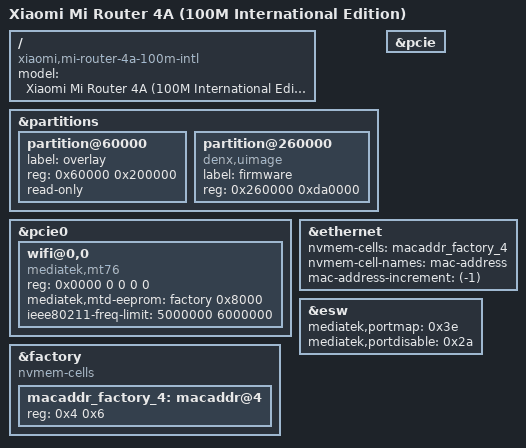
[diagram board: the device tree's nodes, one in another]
// SPDX-License-Identifier: GPL-2.0-or-later OR MIT

#include "mt7628an_xiaomi_mi-router-4.dtsi"

/ {
	compatible = "xiaomi,mi-router-4a-100m-intl", "mediatek,mt7628an-soc";
	model = "Xiaomi Mi Router 4A (100M International Edition)";
};

&partitions {
	partition@60000 {
		label = "overlay";
		reg = <0x60000 0x200000>;
		read-only;
	};

	partition@260000 {
		label = "firmware";
		reg = <0x260000 0xda0000>;
		compatible = "denx,uimage";
	};
};

&pcie {
	status = "okay";
};

&pcie0 {
	wifi@0,0 {
		compatible = "mediatek,mt76";
		reg = <0x0000 0 0 0 0>;
		mediatek,mtd-eeprom = <&factory 0x8000>;
		ieee80211-freq-limit = <5000000 6000000>;
	};
};

&ethernet {
	nvmem-cells = <&macaddr_factory_4>;
	nvmem-cell-names = "mac-address";
	mac-address-increment = <(-1)>;
};

&esw {
	mediatek,portmap = <0x3e>;
	mediatek,portdisable = <0x2a>;
};

&factory {
	compatible = "nvmem-cells";
	#address-cells = <1>;
	#size-cells = <1>;

	macaddr_factory_4: macaddr@4 {
		reg = <0x4 0x6>;
	};
};
